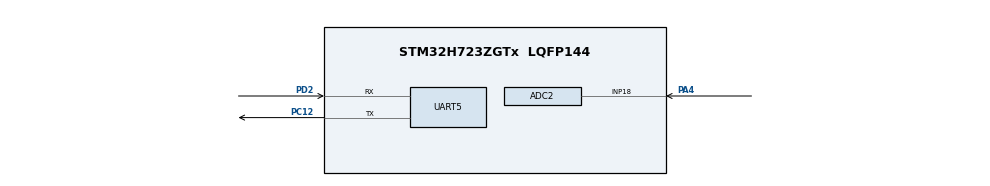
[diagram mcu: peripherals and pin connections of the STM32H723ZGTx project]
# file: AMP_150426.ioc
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ADC2.Channel-0\#ChannelRegularConversion=ADC_CHANNEL_18
ADC2.ContinuousConvMode=ENABLE
ADC2.ConversionDataManagement=ADC_CONVERSIONDATA_DMA_CIRCULAR
ADC2.NbrOfConversionFlag=1
ADC2.OffsetNumber-0\#ChannelRegularConversion=ADC_OFFSET_NONE
ADC2.OffsetSignedSaturation-0\#ChannelRegularConversion=DISABLE
ADC2.Rank-0\#ChannelRegularConversion=1
ADC2.SamplingTime-0\#ChannelRegularConversion=ADC_SAMPLETIME_1CYCLE_5
CORTEX_M7.AccessPermission_Spec=MPU_REGION_FULL_ACCESS
CORTEX_M7.BaseAddress_Spec=0x30000000
CORTEX_M7.CPU_DCache=Disabled
CORTEX_M7.CPU_ICache=Disabled
CORTEX_M7.Enable-Cortex_Memory_Protection_Unit_Region0_Settings=__NULL
CORTEX_M7.MPU_Control=MPU_PRIVILEGED_DEFAULT
CORTEX_M7.Size_Spec=MPU_REGION_SIZE_512MB
CORTEX_M7.default_mode_Activation=0
Dma.ADC2.0.Direction=DMA_PERIPH_TO_MEMORY
Dma.ADC2.0.EventEnable=DISABLE
Dma.ADC2.0.FIFOMode=DMA_FIFOMODE_DISABLE
Dma.ADC2.0.Instance=DMA1_Stream1
Dma.ADC2.0.MemDataAlignment=DMA_MDATAALIGN_HALFWORD
Dma.ADC2.0.MemInc=DMA_MINC_ENABLE
Dma.ADC2.0.Mode=DMA_CIRCULAR
Dma.ADC2.0.PeriphDataAlignment=DMA_PDATAALIGN_HALFWORD
Dma.ADC2.0.PeriphInc=DMA_PINC_DISABLE
Dma.ADC2.0.Polarity=HAL_DMAMUX_REQ_GEN_RISING
Dma.ADC2.0.Priority=DMA_PRIORITY_LOW
Dma.ADC2.0.RequestNumber=1
Dma.ADC2.0.SignalID=NONE
Dma.ADC2.0.SyncEnable=DISABLE
Dma.ADC2.0.SyncPolarity=HAL_DMAMUX_SYNC_NO_EVENT
Dma.ADC2.0.SyncRequestNumber=1
Dma.ADC2.0.SyncSignalID=NONE
Dma.Request0=ADC2
Mcu.Family=STM32H7
Mcu.Name=STM32H723ZGTx
Mcu.Package=LQFP144
NVIC.DMA1_Stream1_IRQn=true\:0\:0\:false\:false\:true\:false\:true\:true
NVIC.PriorityGroup=NVIC_PRIORITYGROUP_4
PA4.Signal=ADCx_INP18
PC12.Mode=Asynchronous
PC12.Signal=UART5_TX
PD2.Mode=Asynchronous
PD2.Signal=UART5_RX
PH0-OSC_IN.Mode=HSE-External-Clock-Source
PH0-OSC_IN.Signal=RCC_OSC_IN
ProjectManager.HeapSize=0x200
ProjectManager.StackSize=0x400
ProjectManager.TargetToolchain=STM32CubeIDE
RCC.ADCFreq_Value=38750000
RCC.APB1Freq_Value=50000000
RCC.APB2Freq_Value=100000000
RCC.APB3Freq_Value=100000000
RCC.APB4Freq_Value=100000000
RCC.CortexFreq_Value=100000000
RCC.D2PPRE1=RCC_APB1_DIV2
RCC.DIVM1=2
RCC.DIVM2=4
RCC.DIVN1=16
RCC.DIVN2=31
RCC.DIVP2=5
RCC.HCLKFreq_Value=100000000
RCC.PLL2FRACN=0
RCC.PLLSourceVirtual=RCC_PLLSOURCE_HSE
RCC.PWR_Regulator_Voltage_Scale=PWR_REGULATOR_VOLTAGE_SCALE2
RCC.SYSCLKFreq_VALUE=100000000
RCC.SYSCLKSource=RCC_SYSCLKSOURCE_PLLCLK
RCC.USBFreq_Value=100000000
SH.ADCx_INP18.0=ADC2_INP18,IN18-Single-Ended
VP_MEMORYMAP_VS_MEMORYMAP.Mode=CurAppReg
board=custom

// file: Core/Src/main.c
/* USER CODE BEGIN Header */
/**
  ******************************************************************************
  * @file           : main.c
  * @brief          : Main program body
  ******************************************************************************
  * @attention
  *
  * Copyright (c) 2026 STMicroelectronics.
  * All rights reserved.
  *
  * This software is licensed under terms that can be found in the LICENSE file
  * in the root directory of this software component.
  * If no LICENSE file comes with this software, it is provided AS-IS.
  *
  ******************************************************************************
  */
/* USER CODE END Header */
#include "main.h"
#include "adc.h"
#include "dma.h"
#include "usart.h"
#include "gpio.h"

/* USER CODE BEGIN Includes */
#include <string.h>
#include <stdio.h>
#include <velocity.h>
/* USER CODE END Includes */

/* USER CODE BEGIN PD */
#define ADC_BUF_LEN 256
/* USER CODE END PD */

/* USER CODE BEGIN PV */
uint16_t adc1_buf[ADC_BUF_LEN];
uint16_t adc2_buf[ADC_BUF_LEN];
uint16_t data[ADC_BUF_LEN/2];
uint32_t last_activity_time = 0;
int adc1_callback_counter = 0;
int adc2_callback_counter = 0;

int adc1_transfer_complete = 0;
int countLoop = 0;

int blaszka = 0;
int odstep = 0;

int blaszka_serio = 0;

// Fir filter
int Ny=(ADC_BUF_LEN-61+1)/2;

uint32_t time_measurement1;
uint32_t time_measurement2;
uint32_t time_measurement3;
uint8_t flag = 1;
float speed_table[512];

float speed;
const float distance = 2*3.14*0.25;

void calculateSpeed(uint16_t *data);
/* USER CODE END PV */

void SystemClock_Config(void);
static void MPU_Config(void);
/* USER CODE BEGIN PFP */
void calculateSpeed(uint16_t *data) {

}
/* USER CODE END PFP */

int main(void)
{

  /* USER CODE BEGIN 1 */
	float data_fir[Ny];
  /* USER CODE END 1 */

  /* MPU Configuration--------------------------------------------------------*/
  MPU_Config();

  /* MCU Configuration--------------------------------------------------------*/

  /* Reset of all peripherals, Initializes the Flash interface and the Systick. */
  HAL_Init();

  /* Configure the system clock */
  SystemClock_Config();

  /* Initialize all configured peripherals */
  MX_GPIO_Init();
  MX_DMA_Init();
  MX_ADC2_Init();
  MX_UART5_Init();
  /* USER CODE BEGIN 2 */
  HAL_ADC_Start_DMA(&hadc2, (uint32_t *)adc2_buf, ADC_BUF_LEN);

  /* USER CODE END 2 */

  /* Infinite loop */
  /* USER CODE BEGIN WHILE */
  while (1)
  {
	  if (adc1_transfer_complete == 1) {
		  uint32_t now = HAL_GetTick();

		  if (now - last_activity_time > 7000) { // 2 sekundy braku sygnału
		      speed = 0;
		  }
		  /*float data_float[ADC_BUF_LEN];
		  for (int i = 0; i < ADC_BUF_LEN/2; i++) {
		      data_float[i] = (float)data[i];
		  }
		  fir_filter(data_float,ADC_BUF_LEN/2,data_fir);*/
		  blaszka = threshold(data, ADC_BUF_LEN/2);
		  if (blaszka) {
		      last_activity_time = HAL_GetTick();
		  }
		  if (blaszka && flag) {
			  time_measurement1 = HAL_GetTick();

			  flag = 0;
		  } else if (blaszka) {
			  time_measurement2 = HAL_GetTick();
			  if (time_measurement2 - time_measurement1 > 500  ) {
				  time_measurement3 = time_measurement2 - time_measurement1;
				  speed = (3.6*100000*distance)/(time_measurement3*12)-20;
//				  speed = (3.6 * 1000 * distance) / time_measurement3;
				  char msg[32];
				  sprintf(msg, "%.1f\r\n", speed);
				  HAL_UART_Transmit(&huart5, (uint8_t*)msg, strlen(msg), 10);
				  //speed_table[blaszka_serio] = speed;
				  blaszka_serio++;
				  flag = 1;
			  }
		  }
		  adc1_transfer_complete = 0;

	  //countLoop++;
	  }
    /* USER CODE END WHILE */

  }
}

void SystemClock_Config(void)
{
  RCC_OscInitTypeDef RCC_OscInitStruct = {0};
  RCC_ClkInitTypeDef RCC_ClkInitStruct = {0};

  /** Supply configuration update enable
  */
  HAL_PWREx_ConfigSupply(PWR_LDO_SUPPLY);

  /** Configure the main internal regulator output voltage
  */
  __HAL_PWR_VOLTAGESCALING_CONFIG(PWR_REGULATOR_VOLTAGE_SCALE2);

  while(!__HAL_PWR_GET_FLAG(PWR_FLAG_VOSRDY)) {}

  /** Initializes the RCC Oscillators according to the specified parameters
  * in the RCC_OscInitTypeDef structure.
  */
  RCC_OscInitStruct.OscillatorType = RCC_OSCILLATORTYPE_HSE;
  RCC_OscInitStruct.HSEState = RCC_HSE_BYPASS;
  RCC_OscInitStruct.PLL.PLLState = RCC_PLL_ON;
  RCC_OscInitStruct.PLL.PLLSource = RCC_PLLSOURCE_HSE;
  RCC_OscInitStruct.PLL.PLLM = 2;
  RCC_OscInitStruct.PLL.PLLN = 16;
  RCC_OscInitStruct.PLL.PLLP = 2;
  RCC_OscInitStruct.PLL.PLLQ = 2;
  RCC_OscInitStruct.PLL.PLLR = 2;
  RCC_OscInitStruct.PLL.PLLRGE = RCC_PLL1VCIRANGE_3;
  RCC_OscInitStruct.PLL.PLLVCOSEL = RCC_PLL1VCOWIDE;
  RCC_OscInitStruct.PLL.PLLFRACN = 0;
  if (HAL_RCC_OscConfig(&RCC_OscInitStruct) != HAL_OK)
  {
    Error_Handler();
  }

  /** Initializes the CPU, AHB and APB buses clocks
  */
  RCC_ClkInitStruct.ClockType = RCC_CLOCKTYPE_HCLK|RCC_CLOCKTYPE_SYSCLK
                              |RCC_CLOCKTYPE_PCLK1|RCC_CLOCKTYPE_PCLK2
                              |RCC_CLOCKTYPE_D3PCLK1|RCC_CLOCKTYPE_D1PCLK1;
  RCC_ClkInitStruct.SYSCLKSource = RCC_SYSCLKSOURCE_PLLCLK;
  RCC_ClkInitStruct.SYSCLKDivider = RCC_SYSCLK_DIV1;
  RCC_ClkInitStruct.AHBCLKDivider = RCC_HCLK_DIV1;
  RCC_ClkInitStruct.APB3CLKDivider = RCC_APB3_DIV1;
  RCC_ClkInitStruct.APB1CLKDivider = RCC_APB1_DIV2;
  RCC_ClkInitStruct.APB2CLKDivider = RCC_APB2_DIV1;
  RCC_ClkInitStruct.APB4CLKDivider = RCC_APB4_DIV1;

  if (HAL_RCC_ClockConfig(&RCC_ClkInitStruct, FLASH_LATENCY_1) != HAL_OK)
  {
    Error_Handler();
  }
}

/* USER CODE BEGIN 4 */

void HAL_ADC_ConvCpltCallback(ADC_HandleTypeDef* hadc) {

	if (hadc == &hadc2) {
		memcpy(data, adc2_buf, ADC_BUF_LEN);
		adc1_transfer_complete = 1;
	}

}

void HAL_ADC_ConvHalfCpltCallback(ADC_HandleTypeDef* hadc) {

	if (hadc == &hadc2) {
		memcpy(data, adc2_buf, ADC_BUF_LEN/2);
		adc1_transfer_complete = 1;
	}

}
/* USER CODE END 4 */

 /* MPU Configuration */

void MPU_Config(void)
{

  /* Disables the MPU */
  HAL_MPU_Disable();

  /* Enables the MPU */
  HAL_MPU_Enable(MPU_PRIVILEGED_DEFAULT);

}

void Error_Handler(void)
{
  __disable_irq();
  while (1)
  {
  }
}
